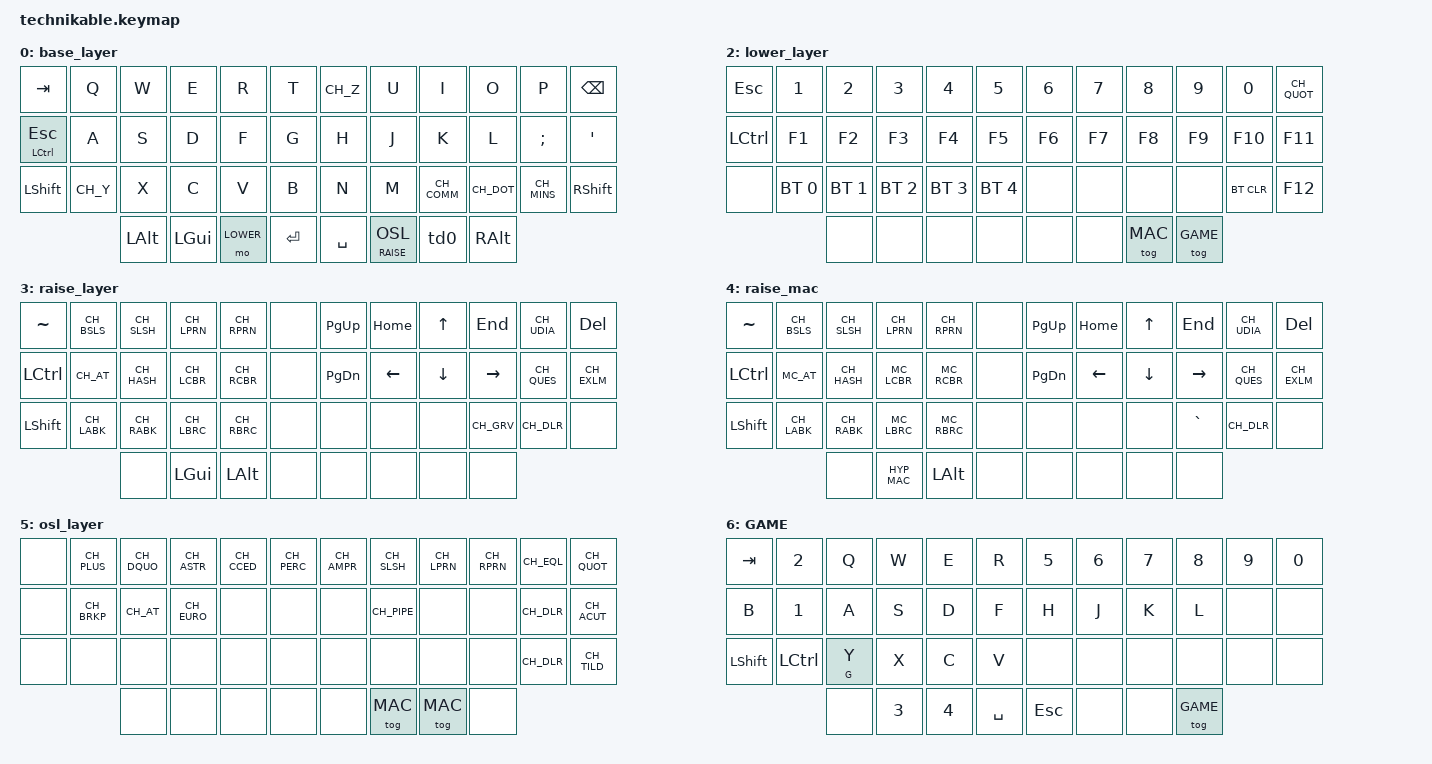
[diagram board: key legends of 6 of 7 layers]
/*
 * Copyright (c) 2022 Pete Johanson
 *
 * SPDX-License-Identifier: MIT
 */

#include <behaviors.dtsi>
#include <dt-bindings/zmk/keys.h>
#include <dt-bindings/zmk/bt.h>
#include <dt-bindings/zmk/outputs.h>
#include "keymap_swiss_de.h"

#define MAC   1
#define LOWER 2
#define RAISE 3
#define MC_RAISE 4
#define OSL   5
#define GAME  6
#define HYP_MAC LC(LA(LGUI))

// Using layer taps on thumbs, having quick tap as well helps w/ repeating space/backspace
&lt { quick_tap_ms = <200>; };
&mt { tapping-term-ms = <150>; };

/ {
    chosen {
       zmk,matrix_transform = &ortho_transform;
    };

    behaviors {
        mo_sl: behavior_mo_sl {
            compatible = "zmk,behavior-hold-tap";
            #binding-cells = <2>;
            flavor = "hold-preferred";
            tapping-term-ms = <150>;
            bindings = <&mo>, <&sl>;
        };
        td0: td_alt_dance {
            compatible = "zmk,behavior-tap-dance";
            #binding-cells = <0>;
            tapping-term-ms = <150>;
            bindings = <&kp LALT>, <&kp RALT>;
            //bindings = <&kp LALT>, <&kp RALT>, <&kp PAD>;
        };
    };

    keymap {
        compatible = "zmk,keymap";

        base_layer {
            bindings = <
//,----------------------------------------------------------------------------------------------------------------------------------------------------.
    &kp TAB      &kp Q        &kp W        &kp E        &kp R        &kp T      &kp CH_Z    &kp U        &kp I      &kp O       &kp P        &kp BSPC
//|-------------+------------+------------+------------+------------+----------+-----------+------------+----------+-----------+------------+----------|
    &mt LCTRL ESC  &kp A      &kp S        &kp D        &kp F        &kp G      &kp H       &kp J        &kp K      &kp L       &kp SEMI     &kp SQT
//|-------------+------------+------------+------------+------------+----------+-----------+------------+----------+-----------+------------+----------|
    &kp LSHFT    &kp CH_Y     &kp X        &kp C        &kp V        &kp B      &kp N       &kp M        &kp CH_COMM &kp CH_DOT &kp CH_MINS  &kp RSHIFT
//|-------------+------------+------------+------------+------------+----------+-----------+------------+----------+-----------+------------+----------|
                              &kp LALT     &kp LGUI     &mo LOWER    &kp RET    &kp SPACE  &mo_sl RAISE OSL &td0 &kp RALT
//,--------------------------+------------+------------+------------+----------+-----------+------------+----------+-----------------------------------.
            >;
        };
        mac {
            bindings = <
//,----------------------------------------------------------------------------------------------------------------------------------------------------.
    &kp TAB      &kp Q        &kp W        &kp E        &kp R        &kp T      &kp CH_Z    &kp U        &kp I      &kp O       &kp P        &kp BSPC
//|-------------+------------+------------+------------+------------+----------+-----------+------------+----------+-----------+------------+----------|
    &mt LCTRL ESC  &kp A      &kp S        &kp D        &kp F        &kp G      &kp H       &kp J        &kp K      &kp L       &kp CH_ODIA  &kp CH_ADIA
//|-------------+------------+------------+------------+------------+----------+-----------+------------+----------+-----------+------------+----------|
    &kp LSHFT    &kp CH_Y     &kp X        &kp C        &kp V        &kp B      &kp N       &kp M        &kp CH_COMM &kp CH_DOT &kp CH_MINS  &kp RSHIFT
//|-------------+------------+------------+------------+------------+----------+-----------+------------+----------+-----------+------------+----------|
                              &kp LGUI     &kp HYP_MAC   &mo LOWER    &kp RET    &kp SPACE  &mo_sl MC_RAISE OSL &kp RALT
//,--------------------------+------------+------------+------------+----------+-----------+------------+----------+-----------------------------------.
            >;
        };
        lower_layer {
            bindings = <
//,----------------------------------------------------------------------------------------------------------------------------------------------------.
    &kp ESC      &kp N1       &kp N2       &kp N3       &kp N4       &kp N5     &kp N6      &kp N7       &kp N8     &kp N9      &kp N0       &kp CH_QUOT
//|-------------+------------+------------+------------+------------+----------+-----------+------------+----------+-----------+------------+----------|
    &kp LCTRL    &kp F1       &kp F2       &kp F3       &kp F4       &kp F5     &kp F6      &kp F7       &kp F8     &kp F9      &kp F10      &kp F11
//|-------------+------------+------------+------------+------------+----------+-----------+------------+----------+-----------+------------+----------|
    &none        &bt BT_SEL 0 &bt BT_SEL 1 &bt BT_SEL 2 &bt BT_SEL 3 &bt BT_SEL 4 &none    &none        &none      &none       &bt BT_CLR   &kp F12
//|-------------+------------+------------+------------+------------+----------+-----------+------------+----------+-----------+------------+----------|
                          	  &none        &none        &none        &none      &none      &none        &tog MAC   &tog GAME
//,--------------------------+------------+------------+------------+----------+-----------+------------+----------+-----------------------------------.
            >;
        };
        raise_layer {
            bindings = <
//,---------------------------------------------------------------------------------------------------------------------------------------------------------.
    &kp TILDE    &kp CH_BSLS  &kp CH_SLSH  &kp CH_LPRN  &kp CH_RPRN  &none      &kp PG_UP    &kp HOME     &kp UP      &kp END    &kp CH_UDIA  &kp DEL
//|-------------+------------+------------+------------+------------+----------+-----------+------------+----------+-----------+------------+----------|
    &kp LCTRL    &kp CH_AT    &kp CH_HASH  &kp CH_LCBR  &kp CH_RCBR  &none      &kp PG_DN    &kp LEFT     &kp DOWN    &kp RIGHT  &kp CH_QUES  &kp CH_EXLM
//|-------------+------------+------------+------------+------------+----------+-----------+------------+----------+-----------+------------+----------|
    &kp LSHFT    &kp CH_LABK  &kp CH_RABK  &kp CH_LBRC  &kp CH_RBRC  &none      &none       &none        &none      &kp CH_GRV  &kp CH_DLR   &none
//|-------------+------------+------------+------------+------------+----------+-----------+------------+----------+-----------+------------+----------|
                          	  &none        &kp LGUI     &kp LALT     &none      &none       &none        &none      &none
//,--------------------------+------------+------------+------------+----------+-----------+------------+----------+-----------------------------------.
            >;
        };
        raise_mac {
                bindings = <
//,---------------------------------------------------------------------------------------------------------------------------------------------------------.
    &kp TILDE    &kp CH_BSLS  &kp CH_SLSH  &kp CH_LPRN  &kp CH_RPRN  &none      &kp PG_UP    &kp HOME     &kp UP      &kp END    &kp CH_UDIA  &kp DEL
//|-------------+------------+------------+------------+------------+----------+-----------+------------+----------+-----------+------------+----------|
    &kp LCTRL    &kp MC_AT    &kp CH_HASH  &kp MC_LCBR  &kp MC_RCBR  &none      &kp PG_DN    &kp LEFT     &kp DOWN    &kp RIGHT  &kp CH_QUES  &kp CH_EXLM
//|-------------+------------+------------+------------+------------+----------+-----------+------------+----------+-----------+------------+----------|
    &kp LSHFT    &kp CH_LABK  &kp CH_RABK  &kp MC_LBRC  &kp MC_RBRC  &none      &none        &none        &none       &kp GRAVE  &kp CH_DLR   &none
//|-------------+------------+------------+------------+------------+----------+-----------+------------+----------+-----------+------------+----------|
                              &none        &kp HYP_MAC  &kp LALT     &none      &none        &none        &none       &none
//,--------------------------+------------+------------+------------+----------+-----------+------------+----------+-----------------------------------.
                >;
        };
        osl_layer {
            bindings = <
//,---------------------------------------------------------------------------------------------------------------------------------------------------------.
    &none        &kp CH_PLUS  &kp CH_DQUO  &kp CH_ASTR  &kp CH_CCED  &kp CH_PERC  &kp CH_AMPR &kp CH_SLSH  &kp CH_LPRN &kp CH_RPRN &kp CH_EQL  &kp CH_QUOT
//|-------------+------------+------------+------------+------------+----------+-----------+------------+----------+-----------+------------+----------|
    &none        &kp CH_BRKP  &kp CH_AT    &kp CH_EURO  &none        &none      &none       &kp CH_PIPE &none        &none      &kp CH_DLR   &kp CH_ACUT
//|-------------+------------+------------+------------+------------+----------+-----------+------------+----------+-----------+------------+----------|
    &none        &none        &none        &none        &none        &none      &none      &none         &none      &none       &kp CH_DLR   &kp CH_TILD
//|-------------+------------+------------+------------+------------+----------+-----------+------------+----------+-----------+------------+----------|
                          	  &none        &none        &none        &none      &none      &tog MAC      &tog MAC      &none
//,--------------------------+------------+------------+------------+----------+-----------+------------+----------+-----------------------------------.
            >;
        };
        GAME {
            bindings = <
//,---------------------------------------------------------------------------------------------------------------------------------------------------------.
    &kp TAB      &kp N2       &kp Q        &kp W        &kp E        &kp R      &kp N5      &kp N6       &kp N7     &kp N8      &kp N9       &kp N0
//|-------------+------------+------------+------------+------------+----------+-----------+------------+----------+-----------+------------+----------|
    &kp B        &kp N1       &kp A        &kp S        &kp D        &kp F      &kp H       &kp J        &kp K      &kp L       &none        &none
//|-------------+------------+------------+------------+------------+----------+-----------+------------+----------+-----------+------------+----------|
    &kp LSHFT    &kp LCTRL    &mt G Y      &kp X        &kp C        &kp V      &none       &none        &none      &none       &none        &none
//|-------------+------------+------------+------------+------------+----------+-----------+------------+----------+-----------+------------+----------|
                              &none        &kp N3       &kp N4       &kp SPACE  &kp ESC     &none        &none      &tog GAME
//,--------------------------+------------+------------+------------+----------+-----------+------------+----------+-----------------------------------.
            >;
        };
    };
};

